# RP2350 register map
Vendor: Raspberry Pi; Series: RP; File version: 0.1
CPU: CM33 r1p0, little endian, MPU, FPU, DSP, VTOR, 4 interrupt priority bits, 52 interrupts, 8 SAU regions
Registers are 32-bit, read-write, reset 0x116 unless marked. A register's access mark holds for its fields unless they carry their own. Offsets are from the block's base; [hi:lo] are bit positions; 'fields as' and 'values as' point back to an identical list.

## IO_BANK0
Base 0x40028000
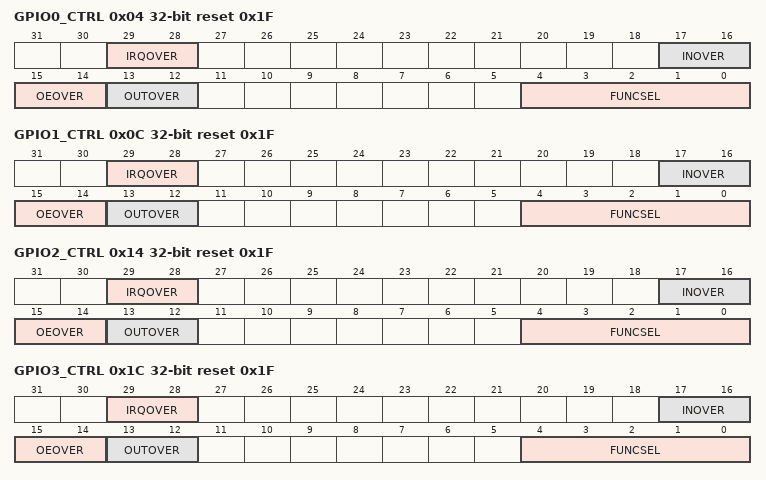
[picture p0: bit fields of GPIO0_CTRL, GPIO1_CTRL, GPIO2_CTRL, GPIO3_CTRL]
0x04 GPIO0_CTRL reset 0x1F
  [29:28] IRQOVER
    0=NORMAL (don't invert the interrupt); 1=INVERT (invert the interrupt); 2=LOW (drive interrupt low); 3=HIGH (drive interrupt high)
  [17:16] INOVER
    0=NORMAL (don't invert the peri input); 1=INVERT (invert the peri input); 2=LOW (drive peri input low); 3=HIGH (drive peri input high)
  [15:14] OEOVER
    0=NORMAL (drive output enable from peripheral signal selected by funcsel); 1=INVERT (drive output enable from inverse of peripheral signal selected by funcsel); 2=DISABLE (disable output); 3=ENABLE (enable output)
  [13:12] OUTOVER
    0=NORMAL (drive output from peripheral signal selected by funcsel); 1=INVERT (drive output from inverse of peripheral signal selected by funcsel); 2=LOW (drive output low); 3=HIGH (drive output high)
  [4:0] FUNCSEL — 0-31 -> selects pin function according to the gpio table 31 == NULL
    0=jtag_tck; 1=spi0_rx; 2=uart0_tx; 3=i2c0_sda; 4=pwm_a_0; 5=siob_proc_0; 6=pio0_0; 7=pio1_0; 8=pio2_0; 9=xip_ss_n_1; 10=usb_muxing_overcurr_detect; 31=null
0x0C GPIO1_CTRL reset 0x1F
  [29:28] IRQOVER
    values as GPIO0_CTRL.IRQOVER
  [17:16] INOVER
    values as GPIO0_CTRL.INOVER
  [15:14] OEOVER
    values as GPIO0_CTRL.OEOVER
  [13:12] OUTOVER
    values as GPIO0_CTRL.OUTOVER
  [4:0] FUNCSEL — 0-31 -> selects pin function according to the gpio table 31 == NULL
    0=jtag_tms; 1=spi0_ss_n; 2=uart0_rx; 3=i2c0_scl; 4=pwm_b_0; 5=siob_proc_1; 6=pio0_1; 7=pio1_1; 8=pio2_1; 9=coresight_traceclk; 10=usb_muxing_vbus_detect; 31=null
0x14 GPIO2_CTRL reset 0x1F
  [29:28] IRQOVER
    values as GPIO0_CTRL.IRQOVER
  [17:16] INOVER
    values as GPIO0_CTRL.INOVER
  [15:14] OEOVER
    values as GPIO0_CTRL.OEOVER
  [13:12] OUTOVER
    values as GPIO0_CTRL.OUTOVER
  [4:0] FUNCSEL — 0-31 -> selects pin function according to the gpio table 31 == NULL
    0=jtag_tdi; 1=spi0_sclk; 2=uart0_cts; 3=i2c1_sda; 4=pwm_a_1; 5=siob_proc_2; 6=pio0_2; 7=pio1_2; 8=pio2_2; 9=coresight_tracedata_0; 10=usb_muxing_vbus_en; 11=uart0_tx; 31=null
0x1C GPIO3_CTRL reset 0x1F
  [29:28] IRQOVER
    values as GPIO0_CTRL.IRQOVER
  [17:16] INOVER
    values as GPIO0_CTRL.INOVER
  [15:14] OEOVER
    values as GPIO0_CTRL.OEOVER
  [13:12] OUTOVER
    values as GPIO0_CTRL.OUTOVER
  [4:0] FUNCSEL — 0-31 -> selects pin function according to the gpio table 31 == NULL
    0=jtag_tdo; 1=spi0_tx; 2=uart0_rts; 3=i2c1_scl; 4=pwm_b_1; 5=siob_proc_3; 6=pio0_3; 7=pio1_3; 8=pio2_3; 9=coresight_tracedata_1; 10=usb_muxing_overcurr_detect; 11=uart0_rx; 31=null
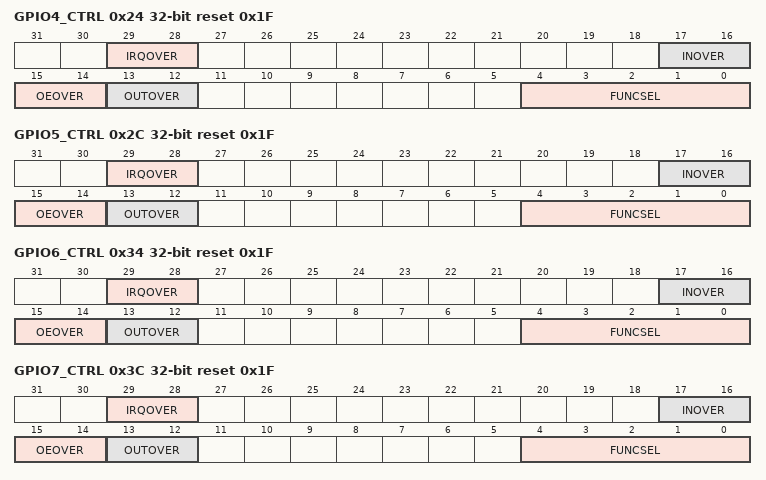
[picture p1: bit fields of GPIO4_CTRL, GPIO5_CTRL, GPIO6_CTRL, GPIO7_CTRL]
0x24 GPIO4_CTRL reset 0x1F
  [29:28] IRQOVER
    values as GPIO0_CTRL.IRQOVER
  [17:16] INOVER
    values as GPIO0_CTRL.INOVER
  [15:14] OEOVER
    values as GPIO0_CTRL.OEOVER
  [13:12] OUTOVER
    values as GPIO0_CTRL.OUTOVER
  [4:0] FUNCSEL — 0-31 -> selects pin function according to the gpio table 31 == NULL
    1=spi0_rx; 2=uart1_tx; 3=i2c0_sda; 4=pwm_a_2; 5=siob_proc_4; 6=pio0_4; 7=pio1_4; 8=pio2_4; 9=coresight_tracedata_2; 10=usb_muxing_vbus_detect; 31=null
0x2C GPIO5_CTRL reset 0x1F
  [29:28] IRQOVER
    values as GPIO0_CTRL.IRQOVER
  [17:16] INOVER
    values as GPIO0_CTRL.INOVER
  [15:14] OEOVER
    values as GPIO0_CTRL.OEOVER
  [13:12] OUTOVER
    values as GPIO0_CTRL.OUTOVER
  [4:0] FUNCSEL — 0-31 -> selects pin function according to the gpio table 31 == NULL
    1=spi0_ss_n; 2=uart1_rx; 3=i2c0_scl; 4=pwm_b_2; 5=siob_proc_5; 6=pio0_5; 7=pio1_5; 8=pio2_5; 9=coresight_tracedata_3; 10=usb_muxing_vbus_en; 31=null
0x34 GPIO6_CTRL reset 0x1F
  [29:28] IRQOVER
    values as GPIO0_CTRL.IRQOVER
  [17:16] INOVER
    values as GPIO0_CTRL.INOVER
  [15:14] OEOVER
    values as GPIO0_CTRL.OEOVER
  [13:12] OUTOVER
    values as GPIO0_CTRL.OUTOVER
  [4:0] FUNCSEL — 0-31 -> selects pin function according to the gpio table 31 == NULL
    1=spi0_sclk; 2=uart1_cts; 3=i2c1_sda; 4=pwm_a_3; 5=siob_proc_6; 6=pio0_6; 7=pio1_6; 8=pio2_6; 10=usb_muxing_overcurr_detect; 11=uart1_tx; 31=null
0x3C GPIO7_CTRL reset 0x1F
  [29:28] IRQOVER
    values as GPIO0_CTRL.IRQOVER
  [17:16] INOVER
    values as GPIO0_CTRL.INOVER
  [15:14] OEOVER
    values as GPIO0_CTRL.OEOVER
  [13:12] OUTOVER
    values as GPIO0_CTRL.OUTOVER
  [4:0] FUNCSEL — 0-31 -> selects pin function according to the gpio table 31 == NULL
    1=spi0_tx; 2=uart1_rts; 3=i2c1_scl; 4=pwm_b_3; 5=siob_proc_7; 6=pio0_7; 7=pio1_7; 8=pio2_7; 10=usb_muxing_vbus_detect; 11=uart1_rx; 31=null
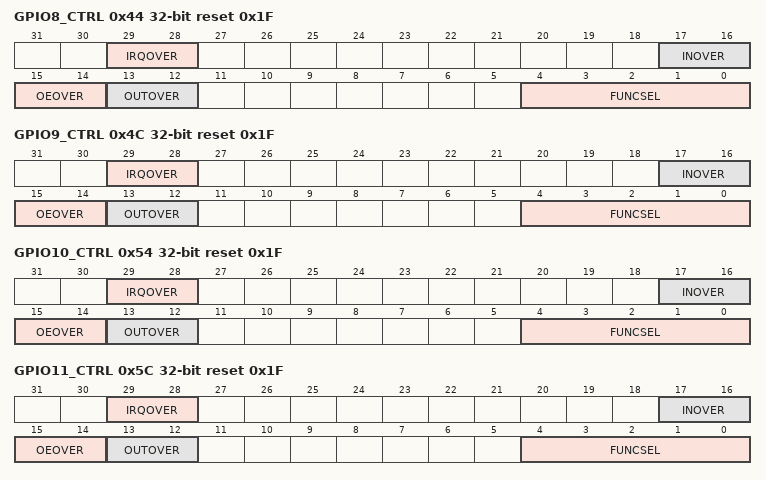
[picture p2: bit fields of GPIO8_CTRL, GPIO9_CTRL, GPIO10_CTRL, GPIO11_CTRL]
0x44 GPIO8_CTRL reset 0x1F
  [29:28] IRQOVER
    values as GPIO0_CTRL.IRQOVER
  [17:16] INOVER
    values as GPIO0_CTRL.INOVER
  [15:14] OEOVER
    values as GPIO0_CTRL.OEOVER
  [13:12] OUTOVER
    values as GPIO0_CTRL.OUTOVER
  [4:0] FUNCSEL — 0-31 -> selects pin function according to the gpio table 31 == NULL
    1=spi1_rx; 2=uart1_tx; 3=i2c0_sda; 4=pwm_a_4; 5=siob_proc_8; 6=pio0_8; 7=pio1_8; 8=pio2_8; 9=xip_ss_n_1; 10=usb_muxing_vbus_en; 31=null
0x4C GPIO9_CTRL reset 0x1F
  [29:28] IRQOVER
    values as GPIO0_CTRL.IRQOVER
  [17:16] INOVER
    values as GPIO0_CTRL.INOVER
  [15:14] OEOVER
    values as GPIO0_CTRL.OEOVER
  [13:12] OUTOVER
    values as GPIO0_CTRL.OUTOVER
  [4:0] FUNCSEL — 0-31 -> selects pin function according to the gpio table 31 == NULL
    1=spi1_ss_n; 2=uart1_rx; 3=i2c0_scl; 4=pwm_b_4; 5=siob_proc_9; 6=pio0_9; 7=pio1_9; 8=pio2_9; 10=usb_muxing_overcurr_detect; 31=null
0x54 GPIO10_CTRL reset 0x1F
  [29:28] IRQOVER
    values as GPIO0_CTRL.IRQOVER
  [17:16] INOVER
    values as GPIO0_CTRL.INOVER
  [15:14] OEOVER
    values as GPIO0_CTRL.OEOVER
  [13:12] OUTOVER
    values as GPIO0_CTRL.OUTOVER
  [4:0] FUNCSEL — 0-31 -> selects pin function according to the gpio table 31 == NULL
    1=spi1_sclk; 2=uart1_cts; 3=i2c1_sda; 4=pwm_a_5; 5=siob_proc_10; 6=pio0_10; 7=pio1_10; 8=pio2_10; 10=usb_muxing_vbus_detect; 11=uart1_tx; 31=null
0x5C GPIO11_CTRL reset 0x1F
  [29:28] IRQOVER
    values as GPIO0_CTRL.IRQOVER
  [17:16] INOVER
    values as GPIO0_CTRL.INOVER
  [15:14] OEOVER
    values as GPIO0_CTRL.OEOVER
  [13:12] OUTOVER
    values as GPIO0_CTRL.OUTOVER
  [4:0] FUNCSEL — 0-31 -> selects pin function according to the gpio table 31 == NULL
    1=spi1_tx; 2=uart1_rts; 3=i2c1_scl; 4=pwm_b_5; 5=siob_proc_11; 6=pio0_11; 7=pio1_11; 8=pio2_11; 10=usb_muxing_vbus_en; 11=uart1_rx; 31=null
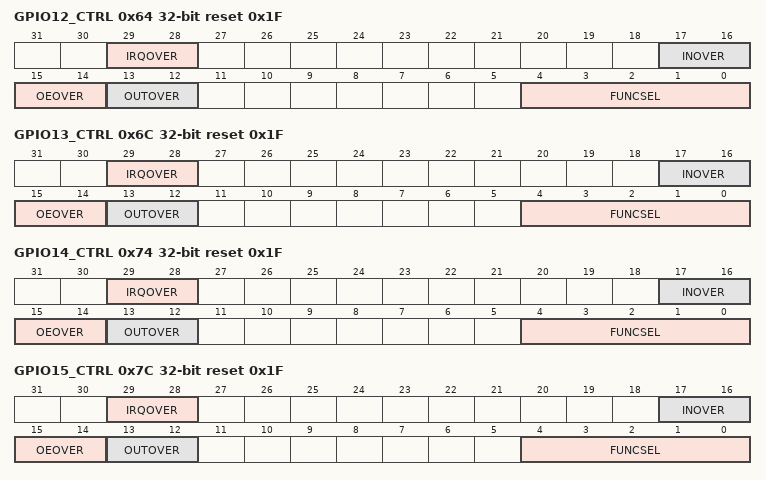
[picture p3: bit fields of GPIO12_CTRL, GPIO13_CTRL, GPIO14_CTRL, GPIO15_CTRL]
0x64 GPIO12_CTRL reset 0x1F
  [29:28] IRQOVER
    values as GPIO0_CTRL.IRQOVER
  [17:16] INOVER
    values as GPIO0_CTRL.INOVER
  [15:14] OEOVER
    values as GPIO0_CTRL.OEOVER
  [13:12] OUTOVER
    values as GPIO0_CTRL.OUTOVER
  [4:0] FUNCSEL — 0-31 -> selects pin function according to the gpio table 31 == NULL
    0=hstx_0; 1=spi1_rx; 2=uart0_tx; 3=i2c0_sda; 4=pwm_a_6; 5=siob_proc_12; 6=pio0_12; 7=pio1_12; 8=pio2_12; 9=clocks_gpin_0; 10=usb_muxing_overcurr_detect; 31=null
0x6C GPIO13_CTRL reset 0x1F
  [29:28] IRQOVER
    values as GPIO0_CTRL.IRQOVER
  [17:16] INOVER
    values as GPIO0_CTRL.INOVER
  [15:14] OEOVER
    values as GPIO0_CTRL.OEOVER
  [13:12] OUTOVER
    values as GPIO0_CTRL.OUTOVER
  [4:0] FUNCSEL — 0-31 -> selects pin function according to the gpio table 31 == NULL
    0=hstx_1; 1=spi1_ss_n; 2=uart0_rx; 3=i2c0_scl; 4=pwm_b_6; 5=siob_proc_13; 6=pio0_13; 7=pio1_13; 8=pio2_13; 9=clocks_gpout_0; 10=usb_muxing_vbus_detect; 31=null
0x74 GPIO14_CTRL reset 0x1F
  [29:28] IRQOVER
    values as GPIO0_CTRL.IRQOVER
  [17:16] INOVER
    values as GPIO0_CTRL.INOVER
  [15:14] OEOVER
    values as GPIO0_CTRL.OEOVER
  [13:12] OUTOVER
    values as GPIO0_CTRL.OUTOVER
  [4:0] FUNCSEL — 0-31 -> selects pin function according to the gpio table 31 == NULL
    0=hstx_2; 1=spi1_sclk; 2=uart0_cts; 3=i2c1_sda; 4=pwm_a_7; 5=siob_proc_14; 6=pio0_14; 7=pio1_14; 8=pio2_14; 9=clocks_gpin_1; 10=usb_muxing_vbus_en; 11=uart0_tx; 31=null
0x7C GPIO15_CTRL reset 0x1F
  [29:28] IRQOVER
    values as GPIO0_CTRL.IRQOVER
  [17:16] INOVER
    values as GPIO0_CTRL.INOVER
  [15:14] OEOVER
    values as GPIO0_CTRL.OEOVER
  [13:12] OUTOVER
    values as GPIO0_CTRL.OUTOVER
  [4:0] FUNCSEL — 0-31 -> selects pin function according to the gpio table 31 == NULL
    0=hstx_3; 1=spi1_tx; 2=uart0_rts; 3=i2c1_scl; 4=pwm_b_7; 5=siob_proc_15; 6=pio0_15; 7=pio1_15; 8=pio2_15; 9=clocks_gpout_1; 10=usb_muxing_overcurr_detect; 11=uart0_rx; 31=null
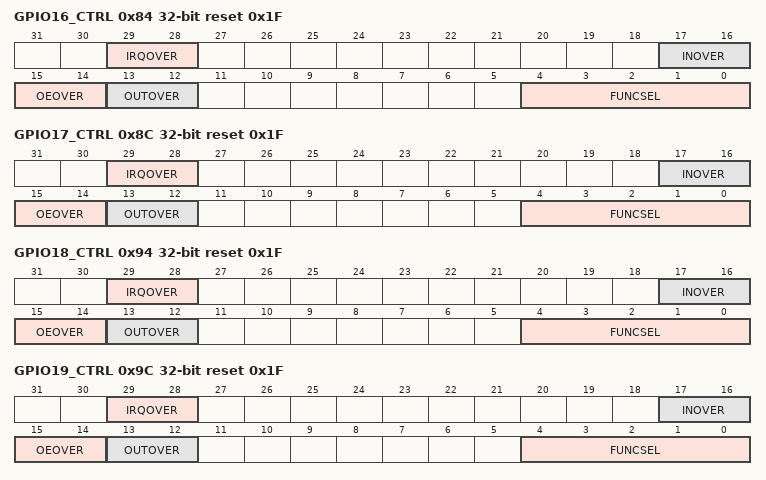
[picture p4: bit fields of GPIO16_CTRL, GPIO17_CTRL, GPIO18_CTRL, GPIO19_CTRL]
0x84 GPIO16_CTRL reset 0x1F
  [29:28] IRQOVER
    values as GPIO0_CTRL.IRQOVER
  [17:16] INOVER
    values as GPIO0_CTRL.INOVER
  [15:14] OEOVER
    values as GPIO0_CTRL.OEOVER
  [13:12] OUTOVER
    values as GPIO0_CTRL.OUTOVER
  [4:0] FUNCSEL — 0-31 -> selects pin function according to the gpio table 31 == NULL
    0=hstx_4; 1=spi0_rx; 2=uart0_tx; 3=i2c0_sda; 4=pwm_a_0; 5=siob_proc_16; 6=pio0_16; 7=pio1_16; 8=pio2_16; 10=usb_muxing_vbus_detect; 31=null
0x8C GPIO17_CTRL reset 0x1F
  [29:28] IRQOVER
    values as GPIO0_CTRL.IRQOVER
  [17:16] INOVER
    values as GPIO0_CTRL.INOVER
  [15:14] OEOVER
    values as GPIO0_CTRL.OEOVER
  [13:12] OUTOVER
    values as GPIO0_CTRL.OUTOVER
  [4:0] FUNCSEL — 0-31 -> selects pin function according to the gpio table 31 == NULL
    0=hstx_5; 1=spi0_ss_n; 2=uart0_rx; 3=i2c0_scl; 4=pwm_b_0; 5=siob_proc_17; 6=pio0_17; 7=pio1_17; 8=pio2_17; 10=usb_muxing_vbus_en; 31=null
0x94 GPIO18_CTRL reset 0x1F
  [29:28] IRQOVER
    values as GPIO0_CTRL.IRQOVER
  [17:16] INOVER
    values as GPIO0_CTRL.INOVER
  [15:14] OEOVER
    values as GPIO0_CTRL.OEOVER
  [13:12] OUTOVER
    values as GPIO0_CTRL.OUTOVER
  [4:0] FUNCSEL — 0-31 -> selects pin function according to the gpio table 31 == NULL
    0=hstx_6; 1=spi0_sclk; 2=uart0_cts; 3=i2c1_sda; 4=pwm_a_1; 5=siob_proc_18; 6=pio0_18; 7=pio1_18; 8=pio2_18; 10=usb_muxing_overcurr_detect; 11=uart0_tx; 31=null
0x9C GPIO19_CTRL reset 0x1F
  [29:28] IRQOVER
    values as GPIO0_CTRL.IRQOVER
  [17:16] INOVER
    values as GPIO0_CTRL.INOVER
  [15:14] OEOVER
    values as GPIO0_CTRL.OEOVER
  [13:12] OUTOVER
    values as GPIO0_CTRL.OUTOVER
  [4:0] FUNCSEL — 0-31 -> selects pin function according to the gpio table 31 == NULL
    0=hstx_7; 1=spi0_tx; 2=uart0_rts; 3=i2c1_scl; 4=pwm_b_1; 5=siob_proc_19; 6=pio0_19; 7=pio1_19; 8=pio2_19; 9=xip_ss_n_1; 10=usb_muxing_vbus_detect; 11=uart0_rx; 31=null
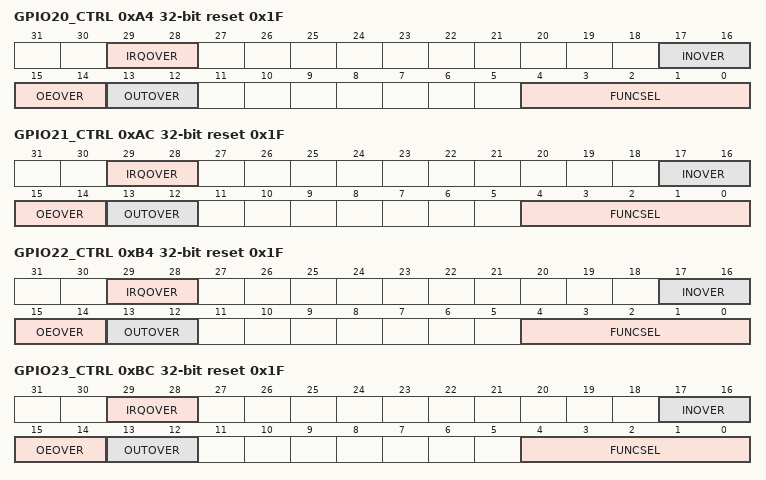
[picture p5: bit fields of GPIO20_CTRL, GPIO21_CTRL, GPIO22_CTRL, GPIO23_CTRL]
0xA4 GPIO20_CTRL reset 0x1F
  [29:28] IRQOVER
    values as GPIO0_CTRL.IRQOVER
  [17:16] INOVER
    values as GPIO0_CTRL.INOVER
  [15:14] OEOVER
    values as GPIO0_CTRL.OEOVER
  [13:12] OUTOVER
    values as GPIO0_CTRL.OUTOVER
  [4:0] FUNCSEL — 0-31 -> selects pin function according to the gpio table 31 == NULL
    1=spi0_rx; 2=uart1_tx; 3=i2c0_sda; 4=pwm_a_2; 5=siob_proc_20; 6=pio0_20; 7=pio1_20; 8=pio2_20; 9=clocks_gpin_0; 10=usb_muxing_vbus_en; 31=null
0xAC GPIO21_CTRL reset 0x1F
  [29:28] IRQOVER
    values as GPIO0_CTRL.IRQOVER
  [17:16] INOVER
    values as GPIO0_CTRL.INOVER
  [15:14] OEOVER
    values as GPIO0_CTRL.OEOVER
  [13:12] OUTOVER
    values as GPIO0_CTRL.OUTOVER
  [4:0] FUNCSEL — 0-31 -> selects pin function according to the gpio table 31 == NULL
    1=spi0_ss_n; 2=uart1_rx; 3=i2c0_scl; 4=pwm_b_2; 5=siob_proc_21; 6=pio0_21; 7=pio1_21; 8=pio2_21; 9=clocks_gpout_0; 10=usb_muxing_overcurr_detect; 31=null
0xB4 GPIO22_CTRL reset 0x1F
  [29:28] IRQOVER
    values as GPIO0_CTRL.IRQOVER
  [17:16] INOVER
    values as GPIO0_CTRL.INOVER
  [15:14] OEOVER
    values as GPIO0_CTRL.OEOVER
  [13:12] OUTOVER
    values as GPIO0_CTRL.OUTOVER
  [4:0] FUNCSEL — 0-31 -> selects pin function according to the gpio table 31 == NULL
    1=spi0_sclk; 2=uart1_cts; 3=i2c1_sda; 4=pwm_a_3; 5=siob_proc_22; 6=pio0_22; 7=pio1_22; 8=pio2_22; 9=clocks_gpin_1; 10=usb_muxing_vbus_detect; 11=uart1_tx; 31=null
0xBC GPIO23_CTRL reset 0x1F
  [29:28] IRQOVER
    values as GPIO0_CTRL.IRQOVER
  [17:16] INOVER
    values as GPIO0_CTRL.INOVER
  [15:14] OEOVER
    values as GPIO0_CTRL.OEOVER
  [13:12] OUTOVER
    values as GPIO0_CTRL.OUTOVER
  [4:0] FUNCSEL — 0-31 -> selects pin function according to the gpio table 31 == NULL
    1=spi0_tx; 2=uart1_rts; 3=i2c1_scl; 4=pwm_b_3; 5=siob_proc_23; 6=pio0_23; 7=pio1_23; 8=pio2_23; 9=clocks_gpout_1; 10=usb_muxing_vbus_en; 11=uart1_rx; 31=null
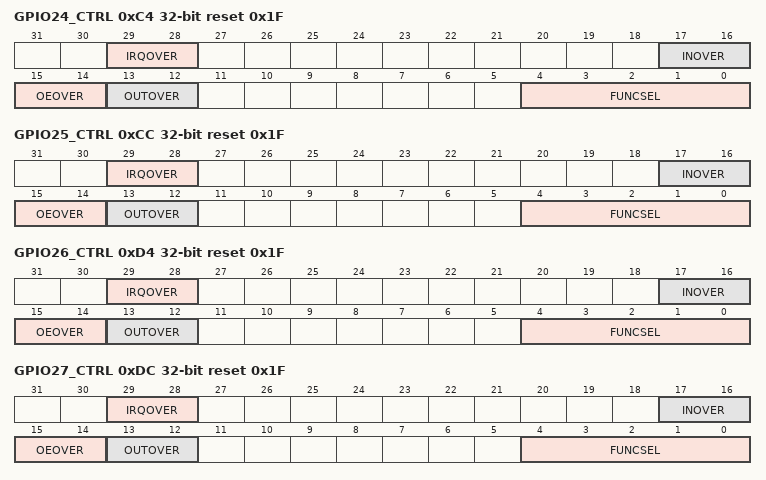
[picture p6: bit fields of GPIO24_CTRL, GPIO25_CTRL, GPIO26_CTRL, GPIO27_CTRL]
0xC4 GPIO24_CTRL reset 0x1F
  [29:28] IRQOVER
    values as GPIO0_CTRL.IRQOVER
  [17:16] INOVER
    values as GPIO0_CTRL.INOVER
  [15:14] OEOVER
    values as GPIO0_CTRL.OEOVER
  [13:12] OUTOVER
    values as GPIO0_CTRL.OUTOVER
  [4:0] FUNCSEL — 0-31 -> selects pin function according to the gpio table 31 == NULL
    1=spi1_rx; 2=uart1_tx; 3=i2c0_sda; 4=pwm_a_4; 5=siob_proc_24; 6=pio0_24; 7=pio1_24; 8=pio2_24; 9=clocks_gpout_2; 10=usb_muxing_overcurr_detect; 31=null
0xCC GPIO25_CTRL reset 0x1F
  [29:28] IRQOVER
    values as GPIO0_CTRL.IRQOVER
  [17:16] INOVER
    values as GPIO0_CTRL.INOVER
  [15:14] OEOVER
    values as GPIO0_CTRL.OEOVER
  [13:12] OUTOVER
    values as GPIO0_CTRL.OUTOVER
  [4:0] FUNCSEL — 0-31 -> selects pin function according to the gpio table 31 == NULL
    1=spi1_ss_n; 2=uart1_rx; 3=i2c0_scl; 4=pwm_b_4; 5=siob_proc_25; 6=pio0_25; 7=pio1_25; 8=pio2_25; 9=clocks_gpout_3; 10=usb_muxing_vbus_detect; 31=null
0xD4 GPIO26_CTRL reset 0x1F
  [29:28] IRQOVER
    values as GPIO0_CTRL.IRQOVER
  [17:16] INOVER
    values as GPIO0_CTRL.INOVER
  [15:14] OEOVER
    values as GPIO0_CTRL.OEOVER
  [13:12] OUTOVER
    values as GPIO0_CTRL.OUTOVER
  [4:0] FUNCSEL — 0-31 -> selects pin function according to the gpio table 31 == NULL
    1=spi1_sclk; 2=uart1_cts; 3=i2c1_sda; 4=pwm_a_5; 5=siob_proc_26; 6=pio0_26; 7=pio1_26; 8=pio2_26; 10=usb_muxing_vbus_en; 11=uart1_tx; 31=null
0xDC GPIO27_CTRL reset 0x1F
  [29:28] IRQOVER
    values as GPIO0_CTRL.IRQOVER
  [17:16] INOVER
    values as GPIO0_CTRL.INOVER
  [15:14] OEOVER
    values as GPIO0_CTRL.OEOVER
  [13:12] OUTOVER
    values as GPIO0_CTRL.OUTOVER
  [4:0] FUNCSEL — 0-31 -> selects pin function according to the gpio table 31 == NULL
    1=spi1_tx; 2=uart1_rts; 3=i2c1_scl; 4=pwm_b_5; 5=siob_proc_27; 6=pio0_27; 7=pio1_27; 8=pio2_27; 10=usb_muxing_overcurr_detect; 11=uart1_rx; 31=null
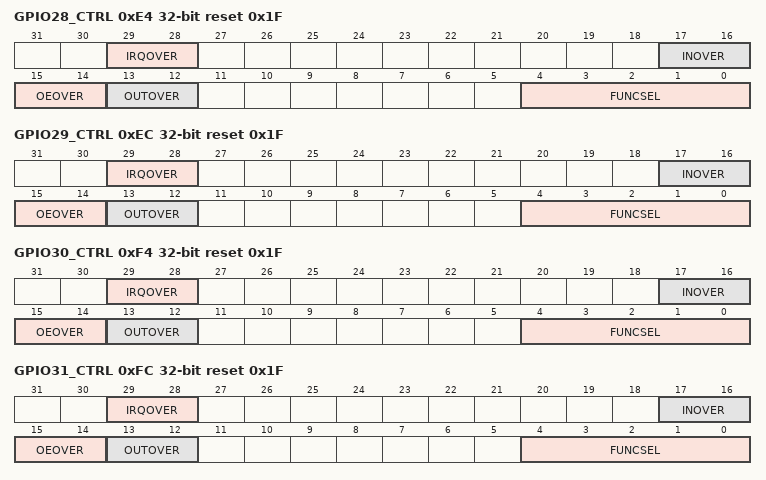
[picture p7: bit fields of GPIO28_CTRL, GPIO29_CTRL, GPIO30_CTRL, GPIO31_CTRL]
0xE4 GPIO28_CTRL reset 0x1F
  [29:28] IRQOVER
    values as GPIO0_CTRL.IRQOVER
  [17:16] INOVER
    values as GPIO0_CTRL.INOVER
  [15:14] OEOVER
    values as GPIO0_CTRL.OEOVER
  [13:12] OUTOVER
    values as GPIO0_CTRL.OUTOVER
  [4:0] FUNCSEL — 0-31 -> selects pin function according to the gpio table 31 == NULL
    1=spi1_rx; 2=uart0_tx; 3=i2c0_sda; 4=pwm_a_6; 5=siob_proc_28; 6=pio0_28; 7=pio1_28; 8=pio2_28; 10=usb_muxing_vbus_detect; 31=null
0xEC GPIO29_CTRL reset 0x1F
  [29:28] IRQOVER
    values as GPIO0_CTRL.IRQOVER
  [17:16] INOVER
    values as GPIO0_CTRL.INOVER
  [15:14] OEOVER
    values as GPIO0_CTRL.OEOVER
  [13:12] OUTOVER
    values as GPIO0_CTRL.OUTOVER
  [4:0] FUNCSEL — 0-31 -> selects pin function according to the gpio table 31 == NULL
    1=spi1_ss_n; 2=uart0_rx; 3=i2c0_scl; 4=pwm_b_6; 5=siob_proc_29; 6=pio0_29; 7=pio1_29; 8=pio2_29; 10=usb_muxing_vbus_en; 31=null
0xF4 GPIO30_CTRL reset 0x1F
  [29:28] IRQOVER
    values as GPIO0_CTRL.IRQOVER
  [17:16] INOVER
    values as GPIO0_CTRL.INOVER
  [15:14] OEOVER
    values as GPIO0_CTRL.OEOVER
  [13:12] OUTOVER
    values as GPIO0_CTRL.OUTOVER
  [4:0] FUNCSEL — 0-31 -> selects pin function according to the gpio table 31 == NULL
    1=spi1_sclk; 2=uart0_cts; 3=i2c1_sda; 4=pwm_a_7; 5=siob_proc_30; 6=pio0_30; 7=pio1_30; 8=pio2_30; 10=usb_muxing_overcurr_detect; 11=uart0_tx; 31=null
0xFC GPIO31_CTRL reset 0x1F
  [29:28] IRQOVER
    values as GPIO0_CTRL.IRQOVER
  [17:16] INOVER
    values as GPIO0_CTRL.INOVER
  [15:14] OEOVER
    values as GPIO0_CTRL.OEOVER
  [13:12] OUTOVER
    values as GPIO0_CTRL.OUTOVER
  [4:0] FUNCSEL — 0-31 -> selects pin function according to the gpio table 31 == NULL
    1=spi1_tx; 2=uart0_rts; 3=i2c1_scl; 4=pwm_b_7; 5=siob_proc_31; 6=pio0_31; 7=pio1_31; 8=pio2_31; 10=usb_muxing_vbus_detect; 11=uart0_rx; 31=null
